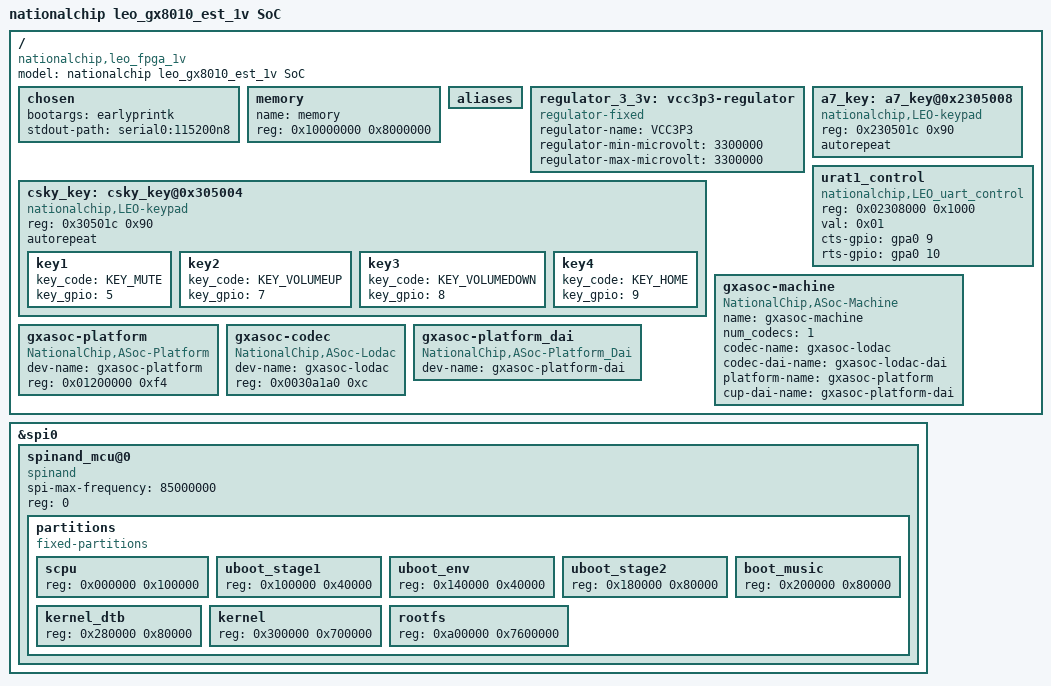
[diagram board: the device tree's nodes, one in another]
/*
 *  Copyright (C) 2013 Steffen Trumtrar <s.trumtrar@pengutronix.de>
 *
 * This program is free software; you can redistribute it and/or modify
 * it under the terms of the GNU General Public License as published by
 * the Free Software Foundation; either version 2 of the License, or
 * (at your option) any later version.
 *
 * This program is distributed in the hope that it will be useful,
 * but WITHOUT ANY WARRANTY; without even the implied warranty of
 * MERCHANTABILITY or FITNESS FOR A PARTICULAR PURPOSE.  See the
 * GNU General Public License for more details.
 *
 * You should have received a copy of the GNU General Public License
 * along with this program.  If not, see <http://www.gnu.org/licenses/>.
 */

/dts-v1/;
/* First 4KB has trampoline code for secondary cores. */
/* /memreserve/ 0x00000000 0x0001000; */

#include "leo.dtsi"

/ {
	model = "nationalchip leo_gx8010_est_1v SoC";
	compatible = "nationalchip,leo_fpga_1v", "nationalchip,leo";

	chosen {
		bootargs = "earlyprintk";
		stdout-path = "serial0:115200n8";
	};

	memory {
		name = "memory";
		device_type = "memory";
		reg = <0x10000000 0x8000000>;
	};

	aliases {
		/* this allow the ethaddr uboot environmnet variable contents
		 * to be added to the gmac1 device tree blob.
		 */
	};

	regulator_3_3v: vcc3p3-regulator {
		compatible = "regulator-fixed";
		regulator-name = "VCC3P3";
		regulator-min-microvolt = <3300000>;
		regulator-max-microvolt = <3300000>;
	};

	a7_key:a7_key@0x2305008{
		compatible = "nationalchip,LEO-keypad";
		reg = <0x230501c 0x90>;
		autorepeat;
	};

	csky_key:csky_key@0x305004{
		compatible = "nationalchip,LEO-keypad";
		reg = <0x30501c 0x90>;
		autorepeat;

        key1:key1{
			key_code  = <KEY_MUTE>;
			key_gpio = <5>;
		};
        key2:key2{
			key_code  = <KEY_VOLUMEUP>;
			key_gpio = <7>;
		};
        key3:key3{
			key_code  = <KEY_VOLUMEDOWN>;
			key_gpio = <8>;
		};
        key4:key4{
			key_code  = <KEY_HOME>;
			key_gpio = <9>;
		};
	};
	urat1_control{
		compatible = "nationalchip,LEO_uart_control";
		reg = <0x02308000 0x1000>;
		val = <0x01>;
		cts-gpio = <&gpa0 9 GPIO_ACTIVE_HIGH>;
		rts-gpio = <&gpa0 10 GPIO_ACTIVE_HIGH>;
	};

	gxasoc-machine {
		name = "gxasoc-machine";
		compatible = "NationalChip,ASoc-Machine";
		num_codecs = <1>;
		codec-name     = "gxasoc-lodac";
		codec-dai-name = "gxasoc-lodac-dai";
		platform-name  = "gxasoc-platform";
		cup-dai-name   = "gxasoc-platform-dai";
		status = "okay";
	};

	gxasoc-platform {
		dev-name   = "gxasoc-platform";
		compatible = "NationalChip,ASoc-Platform";
		reg = <0x01200000 0xf4>;
		reg-names = "gxasoc.aout.regs";
		status = "okay";
	};

	gxasoc-codec {
		dev-name   = "gxasoc-lodac";
		compatible = "NationalChip,ASoc-Lodac";
		reg = <0x0030a1a0 0xc>;
		reg-names = "gxasoc.lodac.regs";
		status = "okay";
	};

	gxasoc-platform_dai {
		dev-name   = "gxasoc-platform-dai";
		compatible = "NationalChip,ASoc-Platform_Dai";
		status = "okay";
	};
};

&spi0{
	status = "okay";

	/* spi nor flash */
	/*M25P@0 {
		compatible = "jedec,spi-nor";
		spi-max-frequency = <85000000>;
		reg = <1>;
		status = "okay";

		partitions {
			#address-cells = <1>;
			#size-cells = <1>;
			compatible = "fixed-partitions";
			scpu {		reg = <0x000000 0x100000>; };
			uboot_stage1 {	reg = <0x100000 0x40000>;  };
			uboot_env {	reg = <0x140000 0x40000>;  };
			uboot_stage2 {	reg = <0x180000 0x80000>;  };
			boot_music {	reg = <0x200000 0x80000>;  };
			kernel_dtb {	reg = <0x280000 0x80000>;  };
			kernel {	reg = <0x300000 0x500000>; };
		};
	};*/

	/* spi nand flash */
	spinand_mcu@0 {
		compatible = "spinand";
		spi-max-frequency = <85000000>;
		reg = <0>;
		status = "okay";

		partitions {
			#address-cells = <1>;
			#size-cells = <1>;
			compatible = "fixed-partitions";
			scpu {		reg = <0x000000 0x100000>; };
			uboot_stage1 {	reg = <0x100000 0x40000>;  };
			uboot_env {	reg = <0x140000 0x40000>;  };
			uboot_stage2 {	reg = <0x180000 0x80000>;  };
			boot_music {	reg = <0x200000 0x80000>;  };
			kernel_dtb {	reg = <0x280000 0x80000>;  };
			kernel {	reg = <0x300000 0x700000>; };
			rootfs {	reg = <0xa00000 0x7600000>;};
		};
	};
};
